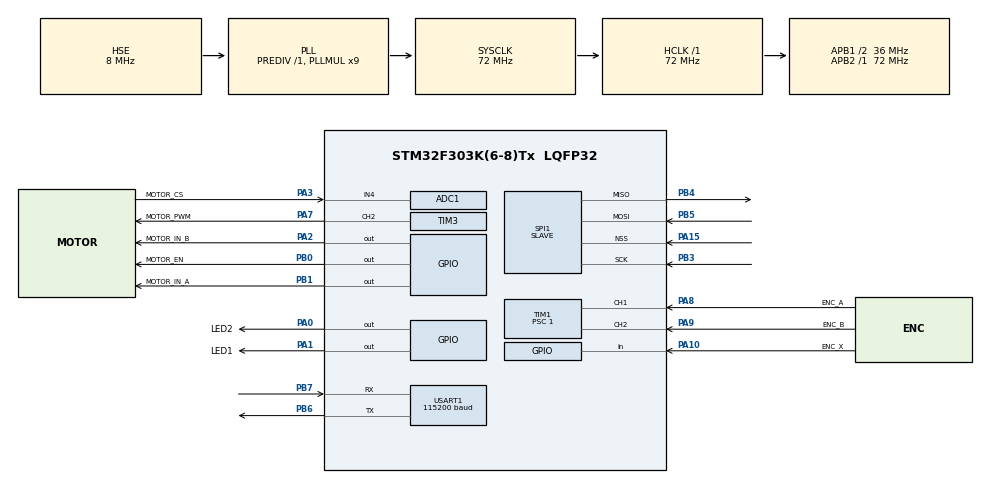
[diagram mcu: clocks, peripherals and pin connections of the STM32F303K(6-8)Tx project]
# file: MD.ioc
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ADC1.Channel-0\#ChannelRegularConversion=ADC_CHANNEL_4
ADC1.NbrOfConversionFlag=1
ADC1.Offset-0\#ChannelRegularConversion=0
ADC1.OffsetNumber-0\#ChannelRegularConversion=ADC_OFFSET_NONE
ADC1.Rank-0\#ChannelRegularConversion=1
ADC1.SamplingTime-0\#ChannelRegularConversion=ADC_SAMPLETIME_1CYCLE_5
ADC1.SubFamily=STM32F303x8
ADC1.master=1
Mcu.Family=STM32F3
Mcu.Name=STM32F303K(6-8)Tx
Mcu.Package=LQFP32
NVIC.PriorityGroup=NVIC_PRIORITYGROUP_4
NVIC.SPI1_IRQn=true\:1\:0\:true\:false\:true\:true
NVIC.TIM6_DAC1_IRQn=true\:0\:0\:false\:false\:true\:true
NVIC.USART1_IRQn=true\:0\:0\:false\:false\:true\:true
PA0.GPIO_Label=LED2
PA0.Signal=GPIO_Output
PA1.GPIO_Label=LED1
PA1.Signal=GPIO_Output
PA10.GPIO_Label=ENC_X
PA10.Signal=GPIO_Input
PA13.Mode=Serial_Wire
PA13.Signal=SYS_JTMS-SWDIO
PA14.Mode=Serial_Wire
PA14.Signal=SYS_JTCK-SWCLK
PA15.Mode=NSS_Signal_Hard_Input
PA15.Signal=SPI1_NSS
PA2.GPIO_Label=MOTOR_IN_B
PA2.Signal=GPIO_Output
PA3.GPIO_Label=MOTOR_CS
PA3.Signal=SharedAnalog_PA3
PA7.GPIO_Label=MOTOR_PWM
PA7.Signal=S_TIM3_CH2
PA8.GPIO_Label=ENC_A
PA8.Signal=S_TIM1_CH1
PA9.GPIO_Label=ENC_B
PA9.Signal=S_TIM1_CH2
PB0.GPIO_Label=MOTOR_EN
PB0.Signal=GPIO_Output
PB1.GPIO_Label=MOTOR_IN_A
PB1.Signal=GPIO_Output
PB3.Mode=Full_Duplex_Slave
PB3.Signal=SPI1_SCK
PB4.Mode=Full_Duplex_Slave
PB4.Signal=SPI1_MISO
PB5.Mode=Full_Duplex_Slave
PB5.Signal=SPI1_MOSI
PB6.Mode=Asynchronous
PB6.Signal=USART1_TX
PB7.Mode=Asynchronous
PB7.Signal=USART1_RX
PF0\ /\ OSC_IN.Mode=HSE-External-Oscillator
PF0\ /\ OSC_IN.Signal=RCC_OSC_IN
PF1\ /\ OSC_OUT.Mode=HSE-External-Oscillator
PF1\ /\ OSC_OUT.Signal=RCC_OSC_OUT
ProjectManager.HeapSize=0x200
ProjectManager.StackSize=0x400
ProjectManager.TargetToolchain=SW4STM32
RCC.AHBFreq_Value=72000000
RCC.APB1CLKDivider=RCC_HCLK_DIV2
RCC.APB1Freq_Value=36000000
RCC.APB1TimFreq_Value=72000000
RCC.APB2Freq_Value=72000000
RCC.APB2TimFreq_Value=72000000
RCC.CortexFreq_Value=72000000
RCC.HCLKFreq_Value=72000000
RCC.HSE_VALUE=8000000
RCC.HSI_VALUE=8000000
RCC.PLLMUL=RCC_PLL_MUL9
RCC.PLLSourceVirtual=RCC_PLLSOURCE_HSE
RCC.SYSCLKFreq_VALUE=72000000
RCC.SYSCLKSourceVirtual=RCC_SYSCLKSOURCE_PLLCLK
SH.S_TIM1_CH1.0=TIM1_CH1,Encoder_Interface
SH.S_TIM1_CH2.0=TIM1_CH2,Encoder_Interface
SH.S_TIM3_CH2.0=TIM3_CH2,PWM Generation2 CH2
SH.SharedAnalog_PA3.0=GPIO_Analog
SH.SharedAnalog_PA3.1=ADC1_IN4,IN4-Single-Ended
SPI1.DataSize=SPI_DATASIZE_8BIT
SPI1.Direction=SPI_DIRECTION_2LINES
SPI1.Mode=SPI_MODE_SLAVE
SPI1.VirtualNSS=VM_NSSHARD
SPI1.VirtualType=VM_SLAVE
TIM1.CounterMode=TIM_COUNTERMODE_UP
TIM1.EncoderMode=TIM_ENCODERMODE_TI12
TIM1.Period=65535
TIM1.Prescaler=1
TIM3.Channel-PWM\ Generation2\ CH2=TIM_CHANNEL_2
TIM3.Period=2400-1
TIM3.Prescaler=1
TIM6.AutoReloadPreload=TIM_AUTORELOAD_PRELOAD_DISABLE
TIM6.Period=36000-1
TIM6.Prescaler=20-1
TIM6.TIM_MasterOutputTrigger=TIM_TRGO_RESET
USART1.BaudRate=115200
USART1.DMADisableonRxErrorParam=ADVFEATURE_DMA_ENABLEONRXERROR
USART1.VirtualMode-Asynchronous=VM_ASYNC
VP_TIM6_VS_ClockSourceINT.Mode=Enable_Timer
board=custom

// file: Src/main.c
/* USER CODE BEGIN Header */
/**
  ******************************************************************************
  * @file           : main.c
  * @brief          : Main program body
  ******************************************************************************
  ** This notice applies to any and all portions of this file
  * that are not between comment pairs USER CODE BEGIN and
  * USER CODE END. Other portions of this file, whether
  * inserted by the user or by software development tools
  * are owned by their respective copyright owners.
  *
  * COPYRIGHT(c) 2019 STMicroelectronics
  *
  * Redistribution and use in source and binary forms, with or without modification,
  * are permitted provided that the following conditions are met:
  *   1. Redistributions of source code must retain the above copyright notice,
  *      this list of conditions and the following disclaimer.
  *   2. Redistributions in binary form must reproduce the above copyright notice,
  *      this list of conditions and the following disclaimer in the documentation
  *      and/or other materials provided with the distribution.
  *   3. Neither the name of STMicroelectronics nor the names of its contributors
  *      may be used to endorse or promote products derived from this software
  *      without specific prior written permission.
  *
  * THIS SOFTWARE IS PROVIDED BY THE COPYRIGHT HOLDERS AND CONTRIBUTORS "AS IS"
  * AND ANY EXPRESS OR IMPLIED WARRANTIES, INCLUDING, BUT NOT LIMITED TO, THE
  * IMPLIED WARRANTIES OF MERCHANTABILITY AND FITNESS FOR A PARTICULAR PURPOSE ARE
  * DISCLAIMED. IN NO EVENT SHALL THE COPYRIGHT HOLDER OR CONTRIBUTORS BE LIABLE
  * FOR ANY DIRECT, INDIRECT, INCIDENTAL, SPECIAL, EXEMPLARY, OR CONSEQUENTIAL
  * DAMAGES (INCLUDING, BUT NOT LIMITED TO, PROCUREMENT OF SUBSTITUTE GOODS OR
  * SERVICES; LOSS OF USE, DATA, OR PROFITS; OR BUSINESS INTERRUPTION) HOWEVER
  * CAUSED AND ON ANY THEORY OF LIABILITY, WHETHER IN CONTRACT, STRICT LIABILITY,
  * OR TORT (INCLUDING NEGLIGENCE OR OTHERWISE) ARISING IN ANY WAY OUT OF THE USE
  * OF THIS SOFTWARE, EVEN IF ADVISED OF THE POSSIBILITY OF SUCH DAMAGE.
  *
  ******************************************************************************
  */
/* USER CODE END Header */

#include "main.h"
#include "adc.h"
#include "spi.h"
#include "tim.h"
#include "usart.h"
#include "gpio.h"

/* USER CODE BEGIN Includes */
#include "main_func.h"
/* USER CODE END Includes */

/* USER CODE BEGIN PV */
/* Private variables ---------------------------------------------------------*/

/* USER CODE END PV */

void SystemClock_Config(void);
/* USER CODE BEGIN PFP */
/* Private function prototypes -----------------------------------------------*/

/* USER CODE END PFP */

int main(void)
{

  /* MCU Configuration--------------------------------------------------------*/

  /* Reset of all peripherals, Initializes the Flash interface and the Systick. */
  HAL_Init();

  /* Configure the system clock */
  SystemClock_Config();

  /* Initialize all configured peripherals */
  MX_GPIO_Init();
  MX_SPI1_Init();
  MX_TIM3_Init();
  MX_USART1_UART_Init();
  MX_TIM1_Init();
  MX_ADC1_Init();
  MX_TIM6_Init();
  /* USER CODE BEGIN 2 */

  Init();

  /* USER CODE END 2 */

  /* Infinite loop */
  while (1)
  {

    /* USER CODE BEGIN 3 */

	  Loop();

  }
  /* USER CODE END 3 */
}

void SystemClock_Config(void)
{
  RCC_OscInitTypeDef RCC_OscInitStruct = {0};
  RCC_ClkInitTypeDef RCC_ClkInitStruct = {0};
  RCC_PeriphCLKInitTypeDef PeriphClkInit = {0};

  /**Initializes the CPU, AHB and APB busses clocks
  */
  RCC_OscInitStruct.OscillatorType = RCC_OSCILLATORTYPE_HSE;
  RCC_OscInitStruct.HSEState = RCC_HSE_ON;
  RCC_OscInitStruct.HSEPredivValue = RCC_HSE_PREDIV_DIV1;
  RCC_OscInitStruct.HSIState = RCC_HSI_ON;
  RCC_OscInitStruct.PLL.PLLState = RCC_PLL_ON;
  RCC_OscInitStruct.PLL.PLLSource = RCC_PLLSOURCE_HSE;
  RCC_OscInitStruct.PLL.PLLMUL = RCC_PLL_MUL9;
  if (HAL_RCC_OscConfig(&RCC_OscInitStruct) != HAL_OK)
  {
    Error_Handler();
  }
  /**Initializes the CPU, AHB and APB busses clocks
  */
  RCC_ClkInitStruct.ClockType = RCC_CLOCKTYPE_HCLK|RCC_CLOCKTYPE_SYSCLK
                              |RCC_CLOCKTYPE_PCLK1|RCC_CLOCKTYPE_PCLK2;
  RCC_ClkInitStruct.SYSCLKSource = RCC_SYSCLKSOURCE_PLLCLK;
  RCC_ClkInitStruct.AHBCLKDivider = RCC_SYSCLK_DIV1;
  RCC_ClkInitStruct.APB1CLKDivider = RCC_HCLK_DIV2;
  RCC_ClkInitStruct.APB2CLKDivider = RCC_HCLK_DIV1;

  if (HAL_RCC_ClockConfig(&RCC_ClkInitStruct, FLASH_LATENCY_2) != HAL_OK)
  {
    Error_Handler();
  }
  PeriphClkInit.PeriphClockSelection = RCC_PERIPHCLK_USART1|RCC_PERIPHCLK_TIM1
                              |RCC_PERIPHCLK_ADC12;
  PeriphClkInit.Usart1ClockSelection = RCC_USART1CLKSOURCE_PCLK1;
  PeriphClkInit.Adc12ClockSelection = RCC_ADC12PLLCLK_DIV1;
  PeriphClkInit.Tim1ClockSelection = RCC_TIM1CLK_HCLK;
  if (HAL_RCCEx_PeriphCLKConfig(&PeriphClkInit) != HAL_OK)
  {
    Error_Handler();
  }
}

void Error_Handler(void)
{
  while(1)
  {
  }
}

/************************ (C) COPYRIGHT STMicroelectronics *****END OF FILE****/
